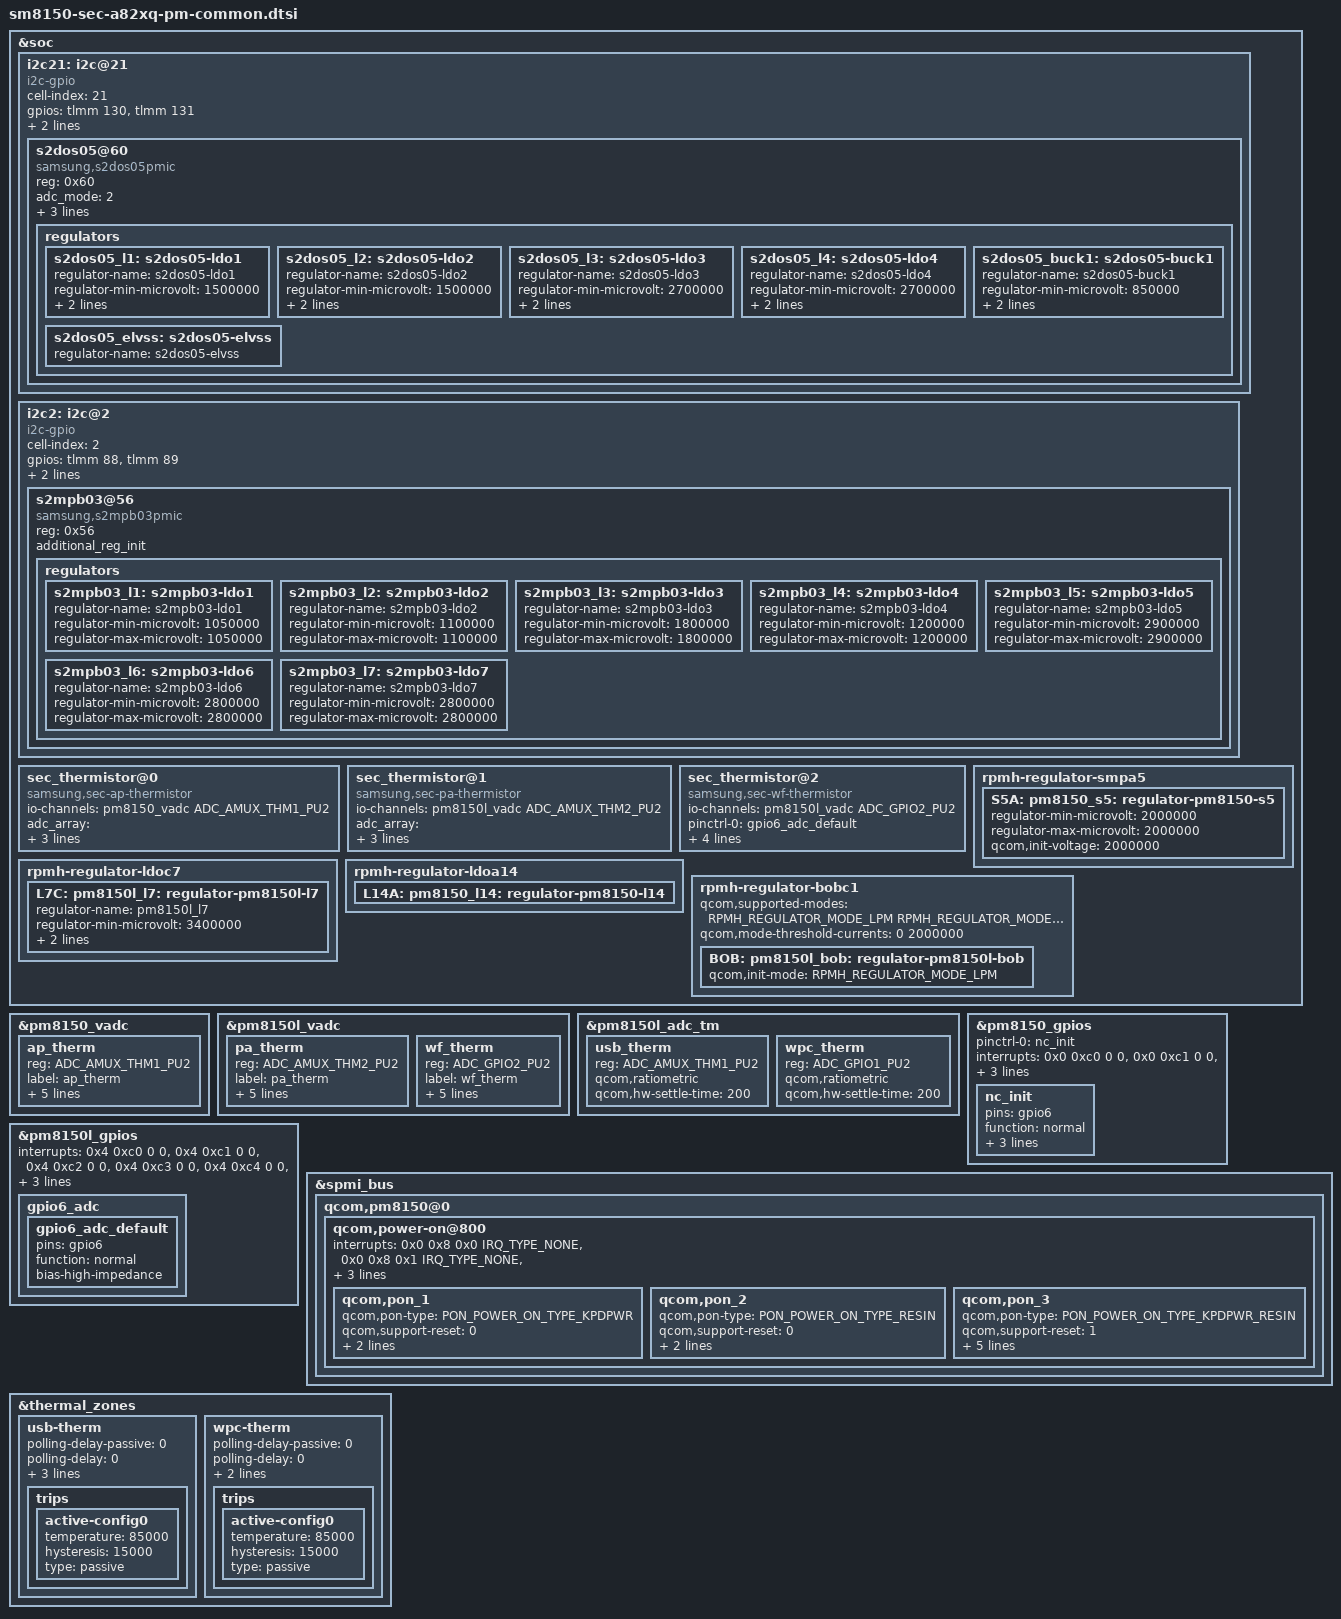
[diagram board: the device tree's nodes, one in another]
/* Copyright (c) 2014, The Linux Foundation. All rights reserved.
 *
 * This program is free software; you can redistribute it and/or modify
 * it under the terms of the GNU General Public License version 2 and
 * only version 2 as published by the Free Software Foundation.
 *
 * This program is distributed in the hope that it will be useful,
 * but WITHOUT ANY WARRANTY; without even the implied warranty of
 * MERCHANTABILITY or FITNESS FOR A PARTICULAR PURPOSE.  See the
 * GNU General Public License for more details.
 */

#include <dt-bindings/regulator/qcom,rpmh-regulator.h>

&soc {
	/* S2DOS05 Display PMIC */
	i2c21: i2c@21 {
		cell-index = <21>;
		compatible = "i2c-gpio";
		gpios = <&tlmm 130 0 /* sda */
			&tlmm 131 0 /* scl */
		>;
		#i2c-gpio,delay-us = <2>;
		#address-cells = <1>;
		#size-cells = <0>;

		pinctrl-names = "default";
		pinctrl-0 = <&s2dos05_i2c_default>;

		s2dos05@60 {
			compatible = "samsung,s2dos05pmic";
			reg = <0x60>;
			adc_mode = <2>; /* 0 : disable, 1 : current meter, 2 : power meter */
			adc_sync_mode = <2>; /* 1 : sync mode, 2 : async mode */

			pinctrl-names = "default";
			pinctrl-0 = <&s2dos05_irq_default>;
			s2dos05,s2dos05_int = <&tlmm 119 0>;

			regulators {
				s2dos05_l1: s2dos05-ldo1 {
					regulator-name = "s2dos05-ldo1";
					regulator-min-microvolt = <1500000>;
					regulator-max-microvolt = <2000000>;
					regulator-active-discharge = <1>;
				};

				s2dos05_l2: s2dos05-ldo2 {
					regulator-name = "s2dos05-ldo2";
					regulator-min-microvolt = <1500000>;
					regulator-max-microvolt = <2000000>;
					regulator-active-discharge = <1>;
				};

				s2dos05_l3: s2dos05-ldo3 {
					regulator-name = "s2dos05-ldo3";
					regulator-min-microvolt = <2700000>;
					regulator-max-microvolt = <3775000>;
					regulator-active-discharge = <1>;
				};

				s2dos05_l4: s2dos05-ldo4 {
					regulator-name = "s2dos05-ldo4";
					regulator-min-microvolt = <2700000>;
					regulator-max-microvolt = <3775000>;
					regulator-active-discharge = <1>;
				};

				s2dos05_buck1: s2dos05-buck1 {
					regulator-name = "s2dos05-buck1";
					regulator-min-microvolt = <850000>;
					regulator-max-microvolt = <2100000>;
					regulator-active-discharge = <1>;
				};

				s2dos05_elvss: s2dos05-elvss {
					regulator-name = "s2dos05-elvss";
				};
			};
		};
	};

	/* S2MPB03 Camera PMIC */
	i2c2: i2c@2 {
		cell-index = <2>;
		compatible = "i2c-gpio";
		gpios = <&tlmm 88 0 /* sda */
			&tlmm 89 0 /* scl */
		>;
		#i2c-gpio,delay-us = <2>;
		#address-cells = <1>;
		#size-cells = <0>;

		pinctrl-names = "default";
		pinctrl-0 = <&s2mpb03_i2c_default>;

		/* S2MPB03 Camera PMIC */
		s2mpb03@56 {
			compatible = "samsung,s2mpb03pmic";
			reg = <0x56>;
			additional_reg_init;

			regulators {
				s2mpb03_l1: s2mpb03-ldo1 {
					regulator-name = "s2mpb03-ldo1";
					regulator-min-microvolt = <1050000>;
					regulator-max-microvolt = <1050000>;
				};

				s2mpb03_l2: s2mpb03-ldo2 {
					regulator-name = "s2mpb03-ldo2";
					regulator-min-microvolt = <1100000>;
					regulator-max-microvolt = <1100000>;
				};

				s2mpb03_l3: s2mpb03-ldo3 {
					regulator-name = "s2mpb03-ldo3";
					regulator-min-microvolt = <1800000>;
					regulator-max-microvolt = <1800000>;
				};

				s2mpb03_l4: s2mpb03-ldo4 {
					regulator-name = "s2mpb03-ldo4";
					regulator-min-microvolt = <1200000>;
					regulator-max-microvolt = <1200000>;
				};

				s2mpb03_l5: s2mpb03-ldo5 {
					regulator-name = "s2mpb03-ldo5";
					regulator-min-microvolt = <2900000>;
					regulator-max-microvolt = <2900000>;
				};

				s2mpb03_l6: s2mpb03-ldo6 {
					regulator-name = "s2mpb03-ldo6";
					regulator-min-microvolt = <2800000>;
					regulator-max-microvolt = <2800000>;
				};

				s2mpb03_l7: s2mpb03-ldo7 {
					regulator-name = "s2mpb03-ldo7";
					regulator-min-microvolt = <2800000>;
					regulator-max-microvolt = <2800000>;
				};
			};
		};
	};

	/* AP Thermistor table */
	sec_thermistor@0 {
		compatible = "samsung,sec-ap-thermistor";
		status = "okay";
		io-channels = <&pm8150_vadc ADC_AMUX_THM1_PU2>;
		io-channel-names = "ap_therm";
		adc_array = <108283 130406 157623 195610 231131 273205 321767 378082 443544
				518252 600681 691479 791328 898053 1004779 1111504 1218230 1324955
				1431681
				1538406 1645132 1751857 1858583>;
		temp_array = <900 850 800 750 700 650 600 550 500
				450 400 350 300 250 200 150 100 50
				0
				(-50) (-100) (-150) (-200)>;
	};

	/* PA Thermistor table */
	sec_thermistor@1 {
		compatible = "samsung,sec-pa-thermistor";
		status = "okay";
		io-channels = <&pm8150l_vadc ADC_AMUX_THM2_PU2>;
		io-channel-names = "pa_therm";
		adc_array = <120967 143966 170793 205633 241868 284461 334353 392290 458434
				533856 618361 711300 811927 919139 1026352 1133564 1240777 1347989
				1455202
				1562414 1669627 1776839 1884052>;
		temp_array = <900 850 800 750 700 650 600 550 500
				450 400 350 300 250 200 150 100 50
				0
				(-50) (-100) (-150) (-200)>;
	};

	/* WiFi Thermistor table */
	sec_thermistor@2 {
		compatible = "samsung,sec-wf-thermistor";
		status = "okay";
		io-channels = <&pm8150l_vadc ADC_GPIO2_PU2>;
		io-channel-names = "wf_therm";
		pinctrl-names = "default";
		pinctrl-0 = <&gpio6_adc_default>;
		adc_array = <124048 146983 173713 208456 244788 287478 337467 395566 461743
				537262 621604 714641 815333 922285 1026794 1131914 1237034 1342154
				1447274
				1552394 1657514 1762634 1867754>;
		temp_array = <900 850 800 750 700 650 600 550 500
				450 400 350 300 250 200 150 100 50
				0
				(-50) (-100) (-150) (-200)>;
	};

	rpmh-regulator-smpa5 {
		S5A: pm8150_s5: regulator-pm8150-s5 {
			regulator-min-microvolt = <2000000>;
			regulator-max-microvolt = <2000000>;
			qcom,init-voltage = <2000000>;
		};
	};

	/* Proximity LEDA */
	rpmh-regulator-ldoc7 {
		L7C: pm8150l_l7: regulator-pm8150l-l7 {
			regulator-name = "pm8150l_l7";
			regulator-min-microvolt = <3400000>;
			regulator-max-microvolt = <3400000>;
			qcom,init-voltage = <3400000>;
		};
	};

	rpmh-regulator-ldoa14 {
		L14A: pm8150_l14: regulator-pm8150-l14 {
			/delete-property/ qcom,proxy-consumer-enable;
			/delete-property/ qcom,proxy-consumer-current;
		};
	};

	/* H/W request */
	rpmh-regulator-bobc1 {
		qcom,supported-modes =
			<RPMH_REGULATOR_MODE_LPM
			 RPMH_REGULATOR_MODE_HPM>;
		qcom,mode-threshold-currents = <0 2000000>;

		BOB: pm8150l_bob: regulator-pm8150l-bob {
			qcom,init-mode = <RPMH_REGULATOR_MODE_LPM>;
		};
	};
};

&pm8150_vadc {
	/delete-node/ skin_therm;
	ap_therm {
		reg = <ADC_AMUX_THM1_PU2>;
		label = "ap_therm";
		qcom,ratiometric;
		qcom,hw-settle-time = <200>;
		qcom,pre-scaling = <1 1>;
		qcom,decimation = <840>;
		qcom,avg-samples = <8>;
	};
};

&pm8150l_vadc {
	/delete-node/ skin_msm_therm;
	pa_therm {
		reg = <ADC_AMUX_THM2_PU2>;
		label = "pa_therm";
		qcom,ratiometric;
		qcom,hw-settle-time = <200>;
		qcom,pre-scaling = <1 1>;
		qcom,decimation = <840>;
		qcom,avg-samples = <8>;
	};

	wf_therm {
		reg = <ADC_GPIO2_PU2>;
		label = "wf_therm";
		qcom,ratiometric;
		qcom,hw-settle-time = <200>;
		qcom,pre-scaling = <1 1>;
		qcom,decimation = <840>;
		qcom,avg-samples = <8>;
	};
};

&pm8150l_adc_tm {
	usb_therm {
		reg = <ADC_AMUX_THM1_PU2>;
		qcom,ratiometric;
		qcom,hw-settle-time = <200>;
	};

	wpc_therm {
		reg = <ADC_GPIO1_PU2>;
		qcom,ratiometric;
		qcom,hw-settle-time = <200>;
	};
};

&pm8150_gpios {
	pinctrl-names = "default";
	pinctrl-0 = <&nc_init>;

	interrupts = <0x0 0xc0 0 0>,
		<0x0 0xc1 0 0>,
		<0x0 0xc2 0 0>,
		<0x0 0xc3 0 0>,
		<0x0 0xc4 0 0>,
		<0x0 0xc5 0 0>,
		<0x0 0xc6 0 0>,
		<0x0 0xc7 0 0>,
		<0x0 0xc8 0 0>,
		<0x0 0xc9 0 0>;
	interrupt-names = "pm8150_gpio1", "pm8150_gpio2",
		"pm8150_gpio3", "pm8150_gpio4",
		"pm8150_gpio5", "pm8150_gpio6",
		"pm8150_gpio7", "pm8150_gpio8",
		"pm8150_gpio9", "pm8150_gpio10";
	/delete-property/ qcom,gpios-disallowed;

	nc_init: nc_init {
		pins = "gpio6";
		function = "normal";
		input-enable;
		bias-pull-down;
		power-source = <0>;
	};
};

&pm8150l_gpios {
	interrupts = <0x4 0xc0 0 0>,
		<0x4 0xc1 0 0>,
		<0x4 0xc2 0 0>,
		<0x4 0xc3 0 0>,
		<0x4 0xc4 0 0>,
		<0x4 0xc5 0 0>,
		<0x4 0xc6 0 0>,
		<0x4 0xc7 0 0>,
		<0x4 0xc8 0 0>,
		<0x4 0xc9 0 0>,
		<0x4 0xca 0 0>,
		<0x4 0xcb 0 0>;
	interrupt-names = "pm8150l_gpio1", "pm8150l_gpio2",
		"pm8150l_gpio3", "pm8150l_gpio4",
		"pm8150l_gpio5", "pm8150l_gpio6",
		"pm8150l_gpio7", "pm8150l_gpio8",
		"pm8150l_gpio9", "pm8150l_gpio10",
		"pm8150l_gpio11", "pm8150l_gpio12";
	/delete-property/ qcom,gpios-disallowed;
};

&pm8150l_gpios {
	gpio6_adc {
		gpio6_adc_default: gpio6_adc_default {
			pins = "gpio6";
			function = "normal";
			bias-high-impedance;
		};
	};
};

&spmi_bus {
	qcom,pm8150@0 {
		qcom,power-on@800 {
			interrupts = <0x0 0x8 0x0 IRQ_TYPE_NONE>,
				     <0x0 0x8 0x1 IRQ_TYPE_NONE>,
					 <0x0 0x8 0x4 IRQ_TYPE_NONE>,
				     <0x0 0x8 0x5 IRQ_TYPE_NONE>;
			interrupt-names = "kpdpwr", "resin",
                    "resin-bark", "kpdpwr-resin-bark";

			qcom,s3-debounce = <128>;
			qcom,pon_1 {
				qcom,pon-type = <PON_POWER_ON_TYPE_KPDPWR>;
				qcom,support-reset = <0>;
				qcom,pull-up = <1>;
				linux,code = <KEY_POWER>;
			};

			qcom,pon_2 {
				qcom,pon-type = <PON_POWER_ON_TYPE_RESIN>;
				qcom,support-reset = <0>;
				qcom,pull-up = <1>;
				linux,code = <KEY_VOLUMEDOWN>;
			};

			qcom,pon_3 {
				qcom,pon-type = <PON_POWER_ON_TYPE_KPDPWR_RESIN>;
				qcom,support-reset = <1>;
				qcom,pull-up = <1>;
				qcom,s1-timer = <6720>;
				qcom,s2-timer = <1000>;
				qcom,s2-type = <8>;
				qcom,use-bark;
			};
		};
	};
};

&thermal_zones {
	 usb-therm {
		polling-delay-passive = <0>;
		polling-delay = <0>;
		thermal-governor = "user_space";
		thermal-sensors = <&pm8150l_adc_tm ADC_AMUX_THM1_PU2>;
		trips {
			active-config0 {
				temperature = <85000>;
				hysteresis = <15000>;
				type = "passive";
			};
		};
	};

	wpc-therm {
		polling-delay-passive = <0>;
		polling-delay = <0>;
		thermal-governor = "user_space";
		thermal-sensors = <&pm8150l_adc_tm ADC_GPIO1_PU2>;
		trips {
			active-config0 {
				temperature = <85000>;
				hysteresis = <15000>;
				type = "passive";
			};
		};
	};
};
